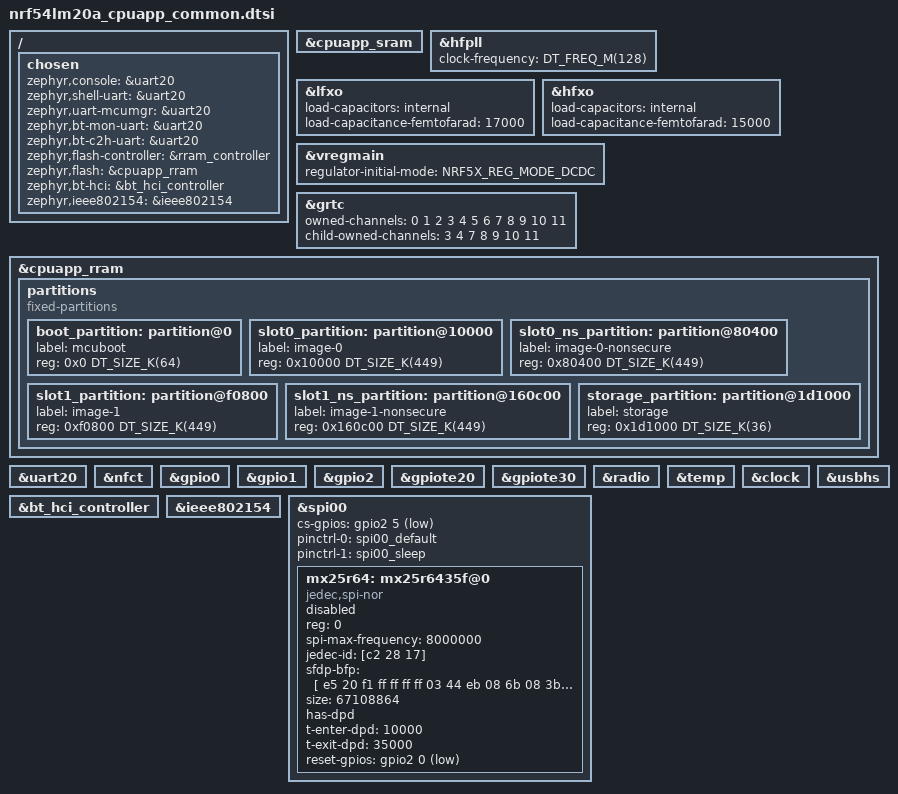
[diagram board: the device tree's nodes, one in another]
/*
 * Copyright (c) 2025 Nordic Semiconductor ASA
 *
 * SPDX-License-Identifier: Apache-2.0
 */

/* This file is common to the secure and non-secure domain */

#include <nordic/nrf54lm20a_enga_cpuapp.dtsi>
#include "nrf54lm20dk_nrf54lm20a-common.dtsi"

/ {
	chosen {
		zephyr,console = &uart20;
		zephyr,shell-uart = &uart20;
		zephyr,uart-mcumgr = &uart20;
		zephyr,bt-mon-uart = &uart20;
		zephyr,bt-c2h-uart = &uart20;
		zephyr,flash-controller = &rram_controller;
		zephyr,flash = &cpuapp_rram;
		zephyr,bt-hci = &bt_hci_controller;
		zephyr,ieee802154 = &ieee802154;
	};
};

&cpuapp_sram {
	status = "okay";
};

&hfpll {
	clock-frequency = <DT_FREQ_M(128)>;
};

&lfxo {
	load-capacitors = "internal";
	load-capacitance-femtofarad = <17000>;
};

&hfxo {
	load-capacitors = "internal";
	load-capacitance-femtofarad = <15000>;
};

&vregmain {
	status = "okay";
	regulator-initial-mode = <NRF5X_REG_MODE_DCDC>;
};

&grtc {
	owned-channels = <0 1 2 3 4 5 6 7 8 9 10 11>;
	/* Channels 7-11 reserved for Zero Latency IRQs, 3-4 for FLPR */
	child-owned-channels = <3 4 7 8 9 10 11>;
	status = "okay";
};

&cpuapp_rram {
	partitions {
		compatible = "fixed-partitions";
		#address-cells = <1>;
		#size-cells = <1>;

		boot_partition: partition@0 {
			label = "mcuboot";
			reg = <0x0 DT_SIZE_K(64)>;
		};

		slot0_partition: partition@10000 {
			label = "image-0";
			reg = <0x10000 DT_SIZE_K(449)>;
		};

		slot0_ns_partition: partition@80400 {
			label = "image-0-nonsecure";
			reg = <0x80400 DT_SIZE_K(449)>;
		};

		slot1_partition: partition@f0800 {
			label = "image-1";
			reg = <0xf0800 DT_SIZE_K(449)>;
		};

		slot1_ns_partition: partition@160c00 {
			label = "image-1-nonsecure";
			reg = <0x160c00 DT_SIZE_K(449)>;
		};

		storage_partition: partition@1d1000 {
			label = "storage";
			reg = <0x1d1000 DT_SIZE_K(36)>;
		};
	};
};

&uart20 {
	status = "okay";
};

&nfct {
	status = "okay";
};

&gpio0 {
	status = "okay";
};

&gpio1 {
	status = "okay";
};

&gpio2 {
	status = "okay";
};

&gpiote20 {
	status = "okay";
};

&gpiote30 {
	status = "okay";
};

&radio {
	status = "okay";
};

&temp {
	status = "okay";
};

&clock {
	status = "okay";
};

&bt_hci_controller {
	status = "okay";
};

&ieee802154 {
	status = "okay";
};

zephyr_udc0: &usbhs {
	status = "okay";
};

&spi00 {
	status = "okay";
	cs-gpios = <&gpio2 5 GPIO_ACTIVE_LOW>;
	pinctrl-0 = <&spi00_default>;
	pinctrl-1 = <&spi00_sleep>;
	pinctrl-names = "default", "sleep";

	mx25r64: mx25r6435f@0 {
		compatible = "jedec,spi-nor";
		status = "disabled";
		reg = <0>;
		spi-max-frequency = <8000000>;
		jedec-id = [c2 28 17];
		sfdp-bfp = [
			e5 20 f1 ff  ff ff ff 03  44 eb 08 6b  08 3b 04 bb
			ee ff ff ff  ff ff 00 ff  ff ff 00 ff  0c 20 0f 52
			10 d8 00 ff  23 72 f5 00  82 ed 04 cc  44 83 48 44
			30 b0 30 b0  f7 c4 d5 5c  00 be 29 ff  f0 d0 ff ff
		];
		size = <67108864>;
		has-dpd;
		t-enter-dpd = <10000>;
		t-exit-dpd = <35000>;
		reset-gpios = <&gpio2 0 GPIO_ACTIVE_LOW>;
	};
};
